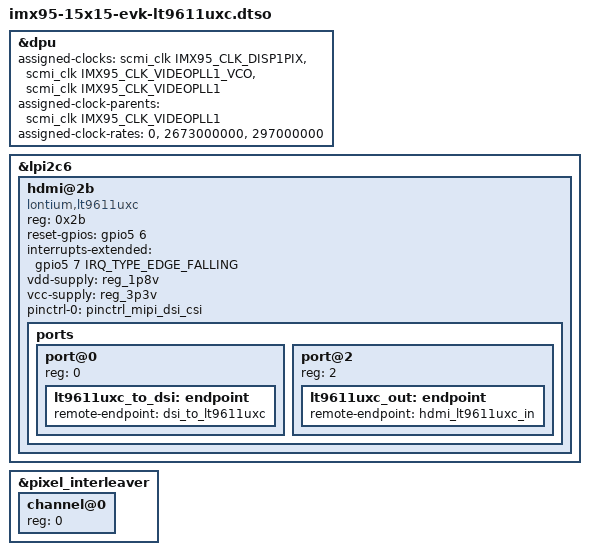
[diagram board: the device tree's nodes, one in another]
// SPDX-License-Identifier: (GPL-2.0+ OR MIT)
/*
 * Copyright 2024,2026 NXP
 */

/dts-v1/;
/plugin/;

#include "imx95-clock.h"
#include "imx95-lt9611uxc-common.dtsi"

&dpu {
	assigned-clocks = <&scmi_clk IMX95_CLK_DISP1PIX>,
			  <&scmi_clk IMX95_CLK_VIDEOPLL1_VCO>,
			  <&scmi_clk IMX95_CLK_VIDEOPLL1>;
	assigned-clock-parents = <&scmi_clk IMX95_CLK_VIDEOPLL1>;
	assigned-clock-rates = <0>, <2673000000>, <297000000>;
};

&lpi2c6 {
	#address-cells = <1>;
	#size-cells = <0>;

	hdmi@2b {
		compatible = "lontium,lt9611uxc";
		reg = <0x2b>;
		reset-gpios = <&gpio5 6 GPIO_ACTIVE_HIGH>;
		interrupts-extended = <&gpio5 7 IRQ_TYPE_EDGE_FALLING>;

		vdd-supply = <&reg_1p8v>;
		vcc-supply = <&reg_3p3v>;

		pinctrl-names = "default";
		pinctrl-0 = <&pinctrl_mipi_dsi_csi>;

		ports {
			#address-cells = <1>;
			#size-cells = <0>;

			port@0 {
				reg = <0>;

				lt9611uxc_to_dsi: endpoint {
					remote-endpoint = <&dsi_to_lt9611uxc>;
				};
			};

			port@2 {
				reg = <2>;

				lt9611uxc_out: endpoint {
					remote-endpoint = <&hdmi_lt9611uxc_in>;
				};
			};
		};
	};
};

&pixel_interleaver {
	#address-cells = <1>;
	#size-cells = <0>;
	status = "okay";

	channel@0 {
		reg = <0>;
		status = "okay";
	};
};
